# ATtiny2313A device description
Architecture: AVR8; Family: tinyAVR
Registers are 8-bit, access not given, no defined reset value unless marked. A register's access mark holds for its fields unless they carry their own. Offsets are from the block's base; [hi:lo] are bit positions.

## FUSE — Fuses
Instances: FUSE 0 in fuses
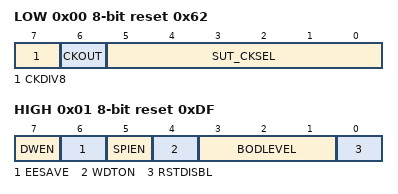
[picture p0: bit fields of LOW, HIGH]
0x00 LOW reset 0x62
  [7] CKDIV8 — Divide clock by 8 internally
  [6] CKOUT — Clock output on PORTD2
  [5:0] SUT_CKSEL — Select Clock Source
    0=EXTCLK_14CK_0MS (Ext. Clock; Start-up time: 14 CK + 0 ms); 16=EXTCLK_14CK_4MS1 (Ext. Clock; Start-up time: 14 CK + 4.1 ms); 32=EXTCLK_14CK_65MS (Ext. Clock; Start-up time: 14 CK + 65 ms); 2=INTRCOSC_4MHZ_14CK_0MS (Int. RC Osc. 4 MHz; Start-up time: 14 CK + 0 ms); 18=INTRCOSC_4MHZ_14CK_4MS1 (Int. RC Osc. 4 MHz; Start-up time: 14 CK + 4.1 ms); 34=INTRCOSC_4MHZ_14CK_65MS (Int. RC Osc. 4 MHz; Start-up time: 14 CK + 65 ms); 4=INTRCOSC_8MHZ_14CK_0MS (Int. RC Osc. 8 MHz; Start-up time: 14 CK + 0 ms); 20=INTRCOSC_8MHZ_14CK_4MS1 (Int. RC Osc. 8 MHz; Start-up time: 14 CK + 4.1 ms); 36=INTRCOSC_8MHZ_14CK_65MS (Int. RC Osc. 8 MHz; Start-up time: 14 CK + 65 ms); 6=INTRCOSC_128KHZ_14CK_0MS (Int. RC Osc. 128 kHz; Start-up time: 14 CK + 0 ms); 22=INTRCOSC_128KHZ_14CK_4MS (Int. RC Osc. 128 kHz; Start-up time: 14 CK + 4 ms); 38=INTRCOSC_128KHZ_14CK_64MS (Int. RC Osc. 128 kHz; Start-up time: 14 CK + 64 ms); 8=EXTXOSC_0MHZ4_0MHZ9_14CK_4MS1 (Ext. Crystal Osc. 0.4-0.9 MHz; Start-up time: 14 CK + 4.1 ms); 24=EXTXOSC_0MHZ4_0MHZ9_14CK_65MS (Ext. Crystal Osc. 0.4-0.9 MHz; Start-up time: 14 CK + 65 ms); 40=EXTXOSC_0MHZ4_0MHZ9_14CK_0MS (Ext. Crystal Osc. 0.4-0.9 MHz; Start-up time: 14 CK + 0 ms); 56=EXTXOSC_0MHZ4_0MHZ9_14CK_4MS1 (Ext. Crystal Osc. 0.4-0.9 MHz; Start-up time: 14 CK + 4.1 ms); 9=EXTXOSC_0MHZ4_0MHZ9_14CK_65MS (Ext. Crystal Osc. 0.4-0.9 MHz; Start-up time: 14 CK + 65 ms); 25=EXTXOSC_0MHZ4_0MHZ9_14CK_0MS (Ext. Crystal Osc. 0.4-0.9 MHz; Start-up time: 14 CK + 0 ms); 41=EXTXOSC_0MHZ4_0MHZ9_14CK_4MS1 (Ext. Crystal Osc. 0.4-0.9 MHz; Start-up time: 14 CK + 4.1 ms); 57=EXTXOSC_0MHZ4_0MHZ9_14CK_65MS (Ext. Crystal Osc. 0.4-0.9 MHz; Start-up time: 14 CK + 65 ms); 10=EXTXOSC_0MHZ9_3MHZ_14CK_4MS1 (Ext. Crystal Osc. 0.9-3.0 MHz; Start-up time: 14 CK + 4.1 ms); 26=EXTXOSC_0MHZ9_3MHZ_14CK_65MS (Ext. Crystal Osc. 0.9-3.0 MHz; Start-up time: 14 CK + 65 ms); 42=EXTXOSC_0MHZ9_3MHZ_14CK_0MS (Ext. Crystal Osc. 0.9-3.0 MHz; Start-up time: 14 CK + 0 ms); 58=EXTXOSC_0MHZ9_3MHZ_14CK_4MS1 (Ext. Crystal Osc. 0.9-3.0 MHz; Start-up time: 14 CK + 4.1 ms); 11=EXTXOSC_0MHZ9_3MHZ_14CK_65MS (Ext. Crystal Osc. 0.9-3.0 MHz; Start-up time: 14 CK + 65 ms); 27=EXTXOSC_0MHZ9_3MHZ_14CK_0MS (Ext. Crystal Osc. 0.9-3.0 MHz; Start-up time: 14 CK + 0 ms); 43=EXTXOSC_0MHZ9_3MHZ_14CK_4MS1 (Ext. Crystal Osc. 0.9-3.0 MHz; Start-up time: 14 CK + 4.1 ms); 59=EXTXOSC_0MHZ9_3MHZ_14CK_65MS (Ext. Crystal Osc. 0.9-3.0 MHz; Start-up time: 14 CK + 65 ms); 12=EXTXOSC_3MHZ_8MHZ_14CK_4MS1 (Ext. Crystal Osc. 3.0-8.0 MHz; Start-up time: 14 CK + 4.1 ms); 28=EXTXOSC_3MHZ_8MHZ_14CK_65MS (Ext. Crystal Osc. 3.0-8.0 MHz; Start-up time: 14 CK + 65 ms); 44=EXTXOSC_3MHZ_8MHZ_14CK_0MS (Ext. Crystal Osc. 3.0-8.0 MHz; Start-up time: 14 CK + 0 ms); 60=EXTXOSC_3MHZ_8MHZ_14CK_4MS1 (Ext. Crystal Osc. 3.0-8.0 MHz; Start-up time: 14 CK + 4.1 ms); 13=EXTXOSC_3MHZ_8MHZ_14CK_65MS (Ext. Crystal Osc. 3.0-8.0 MHz; Start-up time: 14 CK + 65 ms); 29=EXTXOSC_3MHZ_8MHZ_14CK_0MS (Ext. Crystal Osc. 3.0-8.0 MHz; Start-up time: 14 CK + 0 ms); 45=EXTXOSC_3MHZ_8MHZ_14CK_4MS1 (Ext. Crystal Osc. 3.0-8.0 MHz; Start-up time: 14 CK + 4.1 ms); 61=EXTXOSC_3MHZ_8MHZ_14CK_65MS (Ext. Crystal Osc. 3.0-8.0 MHz; Start-up time: 14 CK + 65 ms); 14=EXTXOSC_8MHZ_XX_14CK_4MS1 (Ext. Crystal Osc. 8.0- MHz; Start-up time: 14 CK + 4.1 ms); 30=EXTXOSC_8MHZ_XX_14CK_65MS (Ext. Crystal Osc. 8.0- MHz; Start-up time: 14 CK + 65 ms); 46=EXTXOSC_8MHZ_XX_14CK_0MS (Ext. Crystal Osc. 8.0- MHz; Start-up time: 14 CK + 0 ms); 62=EXTXOSC_8MHZ_XX_14CK_4MS1 (Ext. Crystal Osc. 8.0- MHz; Start-up time: 14 CK + 4.1 ms); 15=EXTXOSC_8MHZ_XX_14CK_65MS (Ext. Crystal Osc. 8.0- MHz; Start-up time: 14 CK + 65 ms); 31=EXTXOSC_8MHZ_XX_14CK_0MS (Ext. Crystal Osc. 8.0- MHz; Start-up time: 14 CK + 0 ms); 47=EXTXOSC_8MHZ_XX_14CK_4MS1 (Ext. Crystal Osc. 8.0- MHz; Start-up time: 14 CK + 4.1 ms); 63=EXTXOSC_8MHZ_XX_14CK_65MS (Ext. Crystal Osc. 8.0- MHz; Start-up time: 14 CK + 65 ms)
0x01 HIGH reset 0xDF
  [7] DWEN — Debug Wire enable
  [6] EESAVE — Preserve EEPROM through the Chip Erase cycle
  [5] SPIEN — Serial program downloading (SPI) enable
  [4] WDTON — Watch-dog Timer always on
  [3:1] BODLEVEL — Brown-out Detector trigger level
    4=4V3 (Brown-out detection at VCC=4.3 V); 5=2V7 (Brown-out detection at VCC=2.7 V); 6=1V8 (Brown-out detection at VCC=1.8 V); 7=DISABLED (Brown-out detection disabled)
  [0] RSTDISBL — External reset disable
0x02 EXTENDED reset 0xFF
  [0] SELFPRGEN — Self Programming enable
